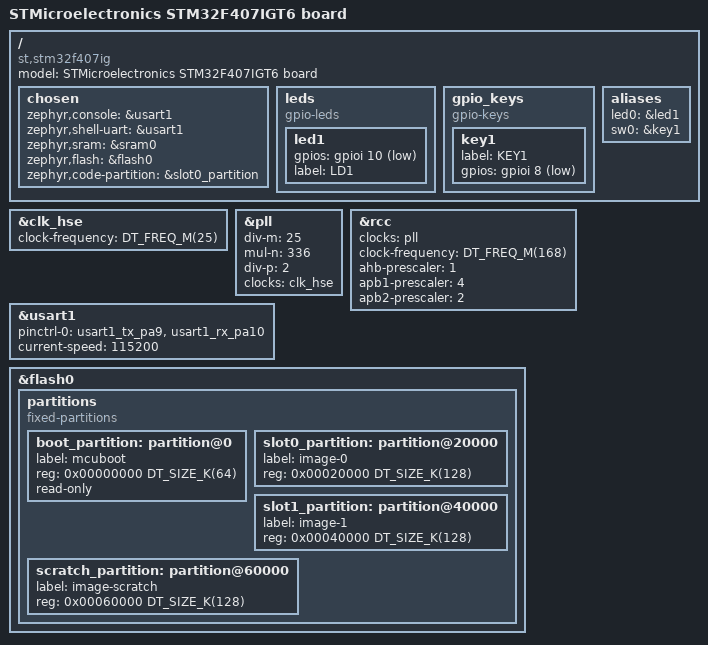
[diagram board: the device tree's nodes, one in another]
/*
 * Copyright (c) 2017 Linaro Limited
 * Copyright (c) 2019 Centaur Analytics, Inc
 *
 * SPDX-License-Identifier: Apache-2.0
 */

/dts-v1/;
#include <st/f4/stm32f407Xg.dtsi>
#include <st/f4/stm32f407i(e-g)tx-pinctrl.dtsi>

/ {
	model = "STMicroelectronics STM32F407IGT6 board";
	compatible = "st,stm32f407ig";

	chosen {
		zephyr,console = &usart1;
		zephyr,shell-uart = &usart1;
		zephyr,sram = &sram0;
		zephyr,flash = &flash0;
		zephyr,code-partition = &slot0_partition;
	};

	leds {
		compatible = "gpio-leds";
		led1: led1 {
			gpios = <&gpioi 10 GPIO_ACTIVE_LOW>;
			label = "LD1";
		};
	};

	gpio_keys {
		compatible = "gpio-keys";
		key1: key1 {
			label = "KEY1";
			gpios = <&gpioi 8 GPIO_ACTIVE_LOW>;
		};
	};

	aliases {
		led0 = &led1;
		sw0 = &key1;
	};
};

&clk_hse {
	clock-frequency = <DT_FREQ_M(25)>;
	status = "okay";
};

&pll {
	div-m = <25>;
	mul-n = <336>;
	div-p = <2>;
	clocks = <&clk_hse>;
	status = "okay";
};

&rcc {
	clocks = <&pll>;
	clock-frequency = <DT_FREQ_M(168)>;
	ahb-prescaler = <1>;
	apb1-prescaler = <4>;
	apb2-prescaler = <2>;
};

&usart1 {
	pinctrl-0 = <&usart1_tx_pa9 &usart1_rx_pa10>;
	pinctrl-names = "default";
	current-speed = <115200>;
	status = "okay";
};

&flash0 {

	partitions {
		compatible = "fixed-partitions";
		#address-cells = <1>;
		#size-cells = <1>;

		boot_partition: partition@0 {
			label = "mcuboot";
			reg = <0x00000000 DT_SIZE_K(64)>;
			read-only;
		};

		/*
		 * The flash starting at offset 0x10000 and ending at
		 * offset 0x1ffff is reserved for use by the application.
		 */

		slot0_partition: partition@20000 {
			label = "image-0";
			reg = <0x00020000 DT_SIZE_K(128)>;
		};
		slot1_partition: partition@40000 {
			label = "image-1";
			reg = <0x00040000 DT_SIZE_K(128)>;
		};
		scratch_partition: partition@60000 {
			label = "image-scratch";
			reg = <0x00060000 DT_SIZE_K(128)>;
		};
	};
};

